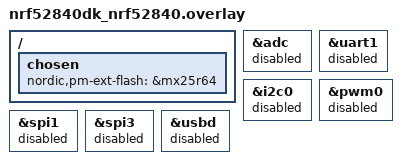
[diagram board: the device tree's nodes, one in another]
/*
 * Copyright (c) 2021 Nordic Semiconductor ASA
 *
 * SPDX-License-Identifier: LicenseRef-Nordic-5-Clause
 */

/ {
	chosen {
		nordic,pm-ext-flash = &mx25r64;
	};
};

/* Disable unused peripherals to reduce power consumption */
&adc {
	status = "disabled";
};
&uart1 {
	status = "disabled";
};
&i2c0 {
	status = "disabled";
};
&pwm0 {
	status = "disabled";
};
&spi1 {
	status = "disabled";
};
&spi3 {
	status = "disabled";
};
&usbd {
	status = "disabled";
};
